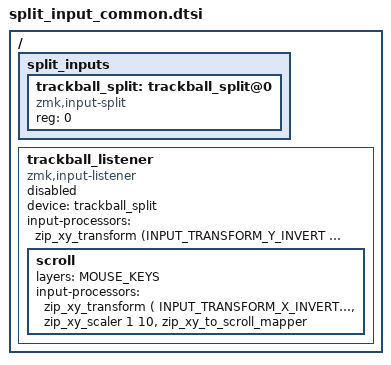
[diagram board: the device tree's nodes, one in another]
#include <dt-bindings/zmk/input_transform.h>
#include <input/processors.dtsi>

/* Layer indices — must match config/offsetkey.keymap #defines */
#define BASE 0
#define LOWER 1
#define MOUSE_KEYS 2
#define MOUSE_TP 3
#define MOUSE_TP_SET 4

/ {
  split_inputs {
    #address-cells = <1>;
    #size-cells = <0>;
    trackball_split: trackball_split@0 {
      compatible = "zmk,input-split";
      reg = <0>;
    };
  };

  trackball_listener: trackball_listener {
    compatible = "zmk,input-listener";
    status = "disabled";
    device = <&trackball_split>;
    input-processors = <&zip_xy_transform (INPUT_TRANSFORM_Y_INVERT | INPUT_TRANSFORM_X_INVERT | INPUT_TRANSFORM_XY_SWAP )>;
    scroll {
      layers = <MOUSE_KEYS>;
      input-processors = <&zip_xy_transform ( INPUT_TRANSFORM_X_INVERT | INPUT_TRANSFORM_XY_SWAP)>, <&zip_xy_scaler 1 10>, <&zip_xy_to_scroll_mapper>;
    };
  };

};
